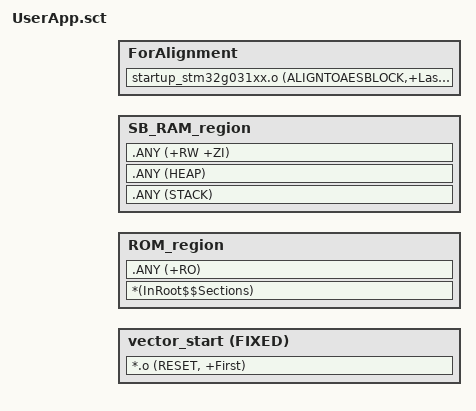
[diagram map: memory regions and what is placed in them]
#! armclang --target=arm-arm-none-eabi  -mcpu=cortex-m0plus -E -xc
; *************************************************************
; *** Scatter-Loading Description File generated by uVision ***
; *************************************************************
#include "..\..\Linker_Common\MDK-ARM\mapping_sbsfu.h"
#include "..\..\Linker_Common\MDK-ARM\mapping_fwimg.h"


LR_ROM (SLOT_ACTIVE_1_START + 0x800) {                      ; 0x800 = IMAGE_OFFSET
  vector_start (SLOT_ACTIVE_1_START + 0x800) FIXED VECTOR_SIZE {
  *.o (RESET, +First)
  }
  ROM_region +0 {
  *(InRoot$$Sections)
  .ANY (+RO)
  }
  SB_RAM_region (SE_REGION_RAM_END + 1) {
  .ANY (STACK)
  .ANY (HEAP)
  .ANY (+RW +ZI)
  }
}

; extra ROM region to make sure the binary size is a multiple of the AES block size (16 bytes)
LR_ROM1(+0) ALIGN(16) {
  ForAlignment +0 {
    startup_stm32g031xx.o (ALIGNTOAESBLOCK,+Last)
  }
}
